# Comparator_A_2 register map
Vendor: Texas Instruments
Peripheral module from a debugger description file (folder msp430).
Registers are 8-bit, read-write, reset 0x0 unless marked. A register's access mark holds for its fields unless they carry their own. Offsets are as the file gives them; lines under a group give offsets from that group; [hi:lo] are bit positions; {n}, {i} and the like mark numbered series; 'fields as' and 'values as' point back to an identical list; <NAME> marks a mode.

## Comparator_A
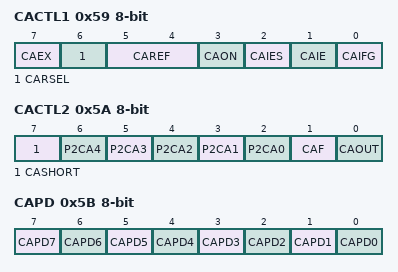
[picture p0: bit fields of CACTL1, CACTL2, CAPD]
0x59 CACTL1 — Comparator A Control 1
  [7] CAEX — Comp. A Exchange Inputs
  [6] CARSEL — Comp. A Internal Reference Enable
  [5:4] CAREF — Comp. A Internal Reference Select 0
    0=Comp. A Int. Ref. Select 0 : Off; 1=Comp. A Int. Ref. Select 1 : 0.25*Vcc; 2=Comp. A Int. Ref. Select 2 : 0.5*Vcc; 3=Comp. A Int. Ref. Select 3 : Vt
  [3] CAON — Comp. A enable
  [2] CAIES — Comp. A Int. Edge Select: 0:rising / 1:falling
  [1] CAIE — Comp. A Interrupt Enable
  [0] CAIFG — Comp. A Interrupt Flag
0x5A CACTL2 — Comparator A Control 2
  [7] CASHORT — Comp. A Short + and - Terminals
  [6] P2CA4 — Comp. A +Terminal Multiplexer
  [5] P2CA3 — Comp. A -Terminal Multiplexer
  [4] P2CA2 — Comp. A -Terminal Multiplexer
  [3] P2CA1 — Comp. A -Terminal Multiplexer
  [2] P2CA0 — Comp. A +Terminal Multiplexer
  [1] CAF — Comp. A Enable Output Filter
  [0] CAOUT — Comp. A Output
0x5B CAPD — Comparator A Port Disable
  [7] CAPD7 — Comp. A Disable Input Buffer of Port Register .7
  [6] CAPD6 — Comp. A Disable Input Buffer of Port Register .6
  [5] CAPD5 — Comp. A Disable Input Buffer of Port Register .5
  [4] CAPD4 — Comp. A Disable Input Buffer of Port Register .4
  [3] CAPD3 — Comp. A Disable Input Buffer of Port Register .3
  [2] CAPD2 — Comp. A Disable Input Buffer of Port Register .2
  [1] CAPD1 — Comp. A Disable Input Buffer of Port Register .1
  [0] CAPD0 — Comp. A Disable Input Buffer of Port Register .0
